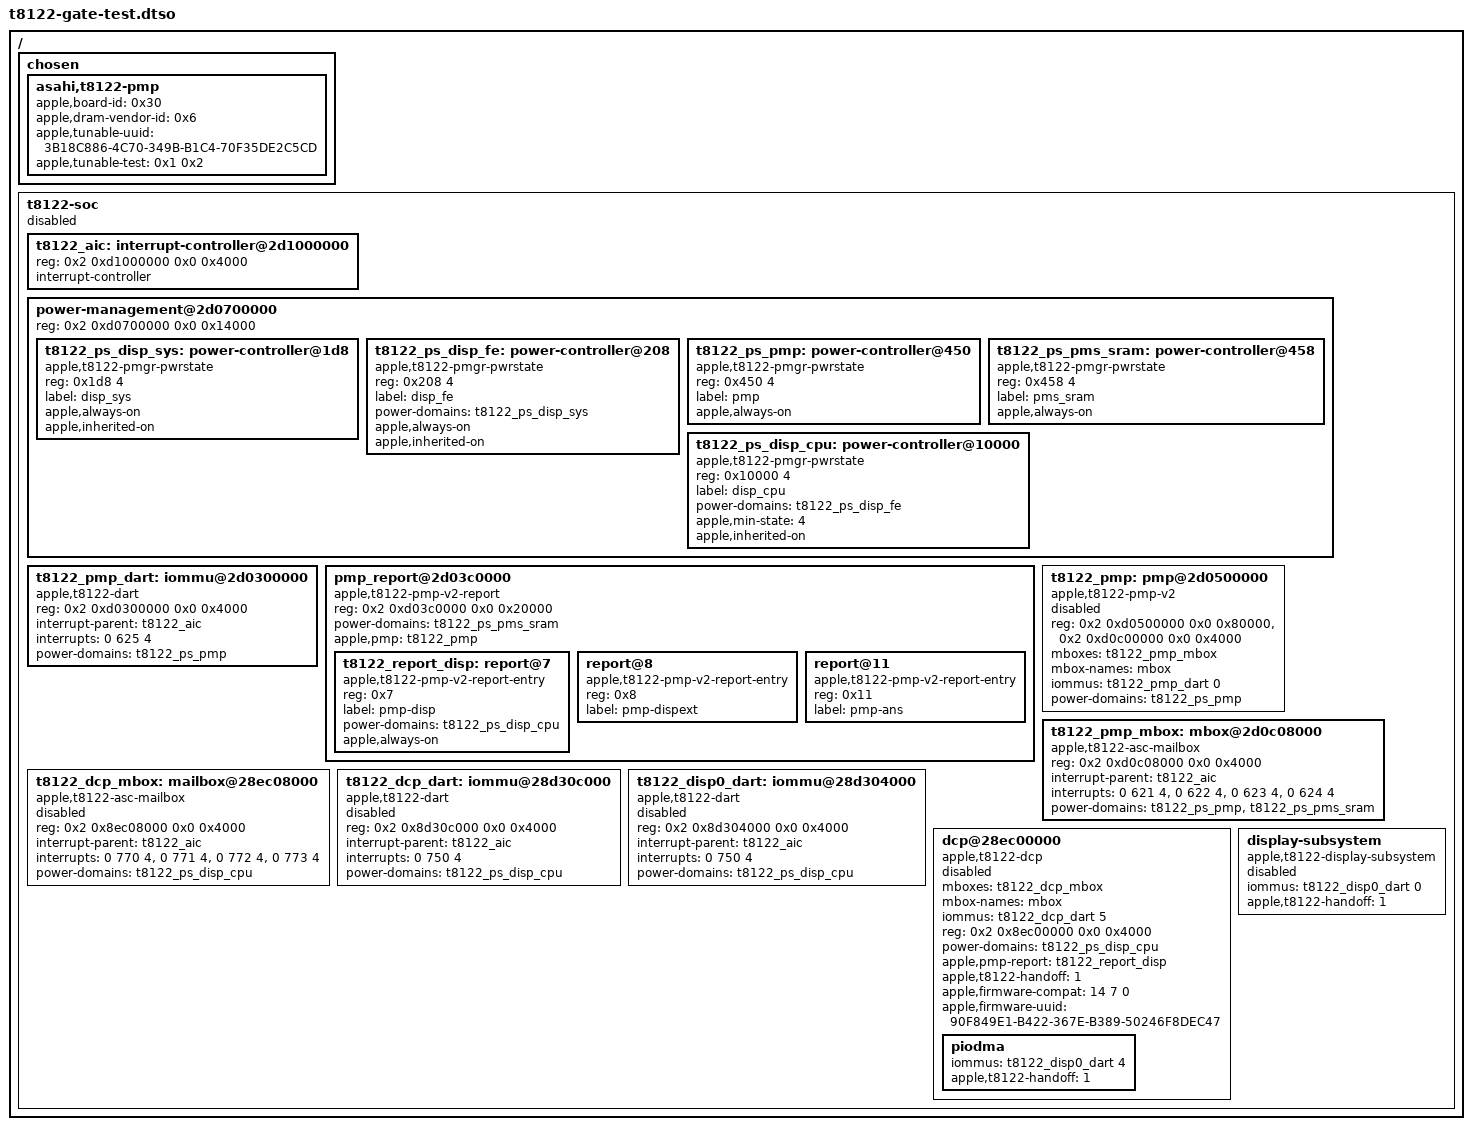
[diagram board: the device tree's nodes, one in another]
// SPDX-License-Identifier: GPL-2.0+ OR MIT
/*
 * Test device tree for the display gate KUnit test: the T8122 display
 * nodes of t8122-dcp.dtsi with the boot loader's handoff applied, the power
 * states they hang from, the PMP topology of t8122.dtsi that the gate
 * reuses, and PMP values. The values are made up: only their presence and
 * the PMP image UUID matter to the gate.
 *
 * The nodes live under their own disabled bus, not /soc, so that they do
 * not collide with the T6030 test tree (both SoCs put the DCP at
 * 0x28ec00000), and no device is created for any of them.
 */

/dts-v1/;
/plugin/;

/ {
	fragment@0 {
		target-path = "/";

		__overlay__ {
			chosen {
				asahi,t8122-pmp {
					apple,board-id = <0x30>;
					apple,dram-vendor-id = <0x6>;
					apple,tunable-uuid = "3B18C886-4C70-349B-B1C4-70F35DE2C5CD";
					apple,tunable-test = <0x1 0x2>;
				};
			};

			t8122-soc {
				#address-cells = <2>;
				#size-cells = <2>;
				status = "disabled";

				t8122_aic: interrupt-controller@2d1000000 {
					reg = <0x2 0xd1000000 0x0 0x4000>;
					interrupt-controller;
					#interrupt-cells = <3>;
				};

				power-management@2d0700000 {
					reg = <0x2 0xd0700000 0x0 0x14000>;
					#address-cells = <1>;
					#size-cells = <1>;

					t8122_ps_disp_sys: power-controller@1d8 {
						compatible = "apple,t8122-pmgr-pwrstate", "apple,t8103-pmgr-pwrstate";
						reg = <0x1d8 4>;
						#power-domain-cells = <0>;
						label = "disp_sys";
						apple,always-on;
						apple,inherited-on;
					};

					t8122_ps_disp_fe: power-controller@208 {
						compatible = "apple,t8122-pmgr-pwrstate", "apple,t8103-pmgr-pwrstate";
						reg = <0x208 4>;
						#power-domain-cells = <0>;
						label = "disp_fe";
						power-domains = <&t8122_ps_disp_sys>;
						apple,always-on;
						apple,inherited-on;
					};

					t8122_ps_pmp: power-controller@450 {
						compatible = "apple,t8122-pmgr-pwrstate", "apple,t8103-pmgr-pwrstate";
						reg = <0x450 4>;
						#power-domain-cells = <0>;
						label = "pmp";
						apple,always-on;
					};

					t8122_ps_pms_sram: power-controller@458 {
						compatible = "apple,t8122-pmgr-pwrstate", "apple,t8103-pmgr-pwrstate";
						reg = <0x458 4>;
						#power-domain-cells = <0>;
						label = "pms_sram";
						apple,always-on;
					};

					t8122_ps_disp_cpu: power-controller@10000 {
						compatible = "apple,t8122-pmgr-pwrstate", "apple,t8103-pmgr-pwrstate";
						reg = <0x10000 4>;
						#power-domain-cells = <0>;
						label = "disp_cpu";
						power-domains = <&t8122_ps_disp_fe>;
						apple,min-state = <4>;
						apple,inherited-on;
					};
				};

				t8122_pmp_dart: iommu@2d0300000 {
					compatible = "apple,t8122-dart", "apple,t8110-dart";
					reg = <0x2 0xd0300000 0x0 0x4000>;
					#iommu-cells = <1>;
					interrupt-parent = <&t8122_aic>;
					interrupts = <0 625 4>;
					power-domains = <&t8122_ps_pmp>;
				};

				pmp_report@2d03c0000 {
					compatible = "apple,t8122-pmp-v2-report";
					reg = <0x2 0xd03c0000 0x0 0x20000>;
					power-domains = <&t8122_ps_pms_sram>;
					#address-cells = <1>;
					#size-cells = <0>;
					apple,pmp = <&t8122_pmp>;

					t8122_report_disp: report@7 {
						compatible = "apple,t8122-pmp-v2-report-entry",
							     "apple,t6000-pmp-v2-report-entry";
						reg = <0x7>;
						label = "pmp-disp";
						#power-domain-cells = <0>;
						power-domains = <&t8122_ps_disp_cpu>;
						apple,always-on;
					};

					report@8 {
						compatible = "apple,t8122-pmp-v2-report-entry",
							     "apple,t6000-pmp-v2-report-entry";
						reg = <0x8>;
						label = "pmp-dispext";
						#power-domain-cells = <0>;
					};

					report@11 {
						compatible = "apple,t8122-pmp-v2-report-entry",
							     "apple,t6000-pmp-v2-report-entry";
						reg = <0x11>;
						label = "pmp-ans";
						#power-domain-cells = <0>;
					};
				};

				t8122_pmp: pmp@2d0500000 {
					compatible = "apple,t8122-pmp-v2", "apple,t6000-pmp-v2";
					reg = <0x2 0xd0500000 0x0 0x80000>,
					      <0x2 0xd0c00000 0x0 0x4000>;
					reg-names = "pmp", "asc";
					mboxes = <&t8122_pmp_mbox>;
					mbox-names = "mbox";
					iommus = <&t8122_pmp_dart 0>;
					power-domains = <&t8122_ps_pmp>;
					status = "disabled";
				};

				t8122_pmp_mbox: mbox@2d0c08000 {
					compatible = "apple,t8122-asc-mailbox", "apple,asc-mailbox-v4";
					reg = <0x2 0xd0c08000 0x0 0x4000>;
					interrupt-parent = <&t8122_aic>;
					interrupts = <0 621 4>, <0 622 4>, <0 623 4>, <0 624 4>;
					interrupt-names = "send-empty", "send-not-empty",
							  "recv-empty", "recv-not-empty";
					#mbox-cells = <0>;
					power-domains = <&t8122_ps_pmp>, <&t8122_ps_pms_sram>;
				};

				t8122_dcp_mbox: mailbox@28ec08000 {
					compatible = "apple,t8122-asc-mailbox", "apple,asc-mailbox-v4";
					reg = <0x2 0x8ec08000 0x0 0x4000>;
					interrupt-parent = <&t8122_aic>;
					interrupts = <0 770 4>, <0 771 4>, <0 772 4>, <0 773 4>;
					interrupt-names = "send-empty", "send-not-empty",
							  "recv-empty", "recv-not-empty";
					power-domains = <&t8122_ps_disp_cpu>;
					#mbox-cells = <0>;
					status = "disabled";
				};

				t8122_dcp_dart: iommu@28d30c000 {
					compatible = "apple,t8122-dart", "apple,t8110-dart";
					reg = <0x2 0x8d30c000 0x0 0x4000>;
					interrupt-parent = <&t8122_aic>;
					interrupts = <0 750 4>;
					#iommu-cells = <1>;
					power-domains = <&t8122_ps_disp_cpu>;
					status = "disabled";
				};

				t8122_disp0_dart: iommu@28d304000 {
					compatible = "apple,t8122-dart", "apple,t8110-dart";
					reg = <0x2 0x8d304000 0x0 0x4000>;
					interrupt-parent = <&t8122_aic>;
					interrupts = <0 750 4>;
					#iommu-cells = <1>;
					power-domains = <&t8122_ps_disp_cpu>;
					status = "disabled";
				};

				dcp@28ec00000 {
					compatible = "apple,t8122-dcp";
					mboxes = <&t8122_dcp_mbox>;
					mbox-names = "mbox";
					iommus = <&t8122_dcp_dart 5>;
					reg-names = "coproc";
					reg = <0x2 0x8ec00000 0x0 0x4000>;
					power-domains = <&t8122_ps_disp_cpu>;
					apple,pmp-report = <&t8122_report_disp>;
					status = "disabled";
					apple,t8122-handoff = <1>;
					apple,firmware-compat = <14 7 0>;
					apple,firmware-uuid = "90F849E1-B422-367E-B389-50246F8DEC47";

					piodma {
						iommus = <&t8122_disp0_dart 4>;
						apple,t8122-handoff = <1>;
					};
				};

				display-subsystem {
					compatible = "apple,t8122-display-subsystem";
					iommus = <&t8122_disp0_dart 0>;
					status = "disabled";
					apple,t8122-handoff = <1>;
				};
			};
		};
	};
};
